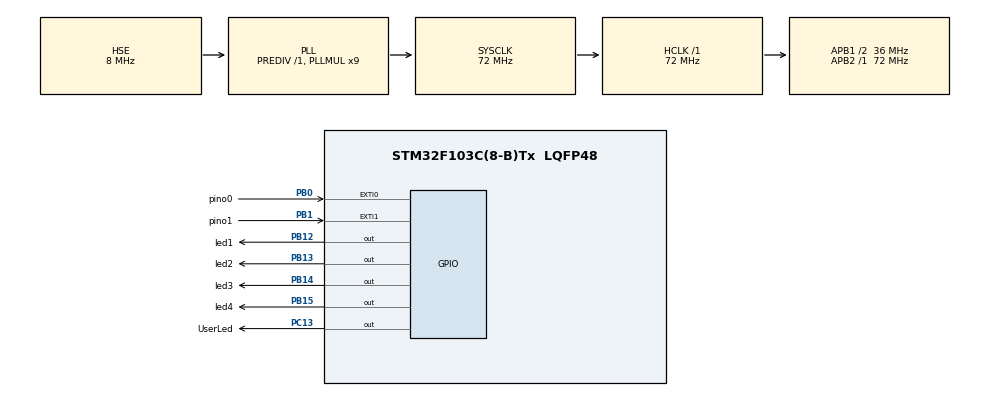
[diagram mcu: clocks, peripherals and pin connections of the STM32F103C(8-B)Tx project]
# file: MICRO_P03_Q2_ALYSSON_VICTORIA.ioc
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Mcu.Family=STM32F1
Mcu.Name=STM32F103C(8-B)Tx
Mcu.Package=LQFP48
NVIC.EXTI0_IRQn=true\:5\:0\:true\:false\:true\:true\:true\:true
NVIC.EXTI1_IRQn=true\:0\:0\:false\:false\:true\:true\:true\:true
NVIC.PriorityGroup=NVIC_PRIORITYGROUP_4
PA13.Mode=Serial_Wire
PA13.Signal=SYS_JTMS-SWDIO
PA14.Mode=Serial_Wire
PA14.Signal=SYS_JTCK-SWCLK
PB0.GPIO_Label=pino0
PB0.GPIO_ModeDefaultEXTI=GPIO_MODE_IT_FALLING
PB0.GPIO_PuPd=GPIO_PULLUP
PB0.Signal=GPXTI0
PB1.GPIO_Label=pino1
PB1.GPIO_ModeDefaultEXTI=GPIO_MODE_IT_FALLING
PB1.GPIO_PuPd=GPIO_PULLUP
PB1.Signal=GPXTI1
PB12.GPIO_Label=led1
PB12.GPIO_Speed=GPIO_SPEED_FREQ_LOW
PB12.PinState=GPIO_PIN_SET
PB12.Signal=GPIO_Output
PB13.GPIO_Label=led2
PB13.GPIO_Speed=GPIO_SPEED_FREQ_LOW
PB13.PinState=GPIO_PIN_SET
PB13.Signal=GPIO_Output
PB14.GPIO_Label=led3
PB14.GPIO_Speed=GPIO_SPEED_FREQ_LOW
PB14.PinState=GPIO_PIN_SET
PB14.Signal=GPIO_Output
PB15.GPIO_Label=led4
PB15.GPIO_Speed=GPIO_SPEED_FREQ_LOW
PB15.PinState=GPIO_PIN_SET
PB15.Signal=GPIO_Output
PC13-TAMPER-RTC.GPIO_Label=UserLed
PC13-TAMPER-RTC.PinState=GPIO_PIN_SET
PC13-TAMPER-RTC.Signal=GPIO_Output
PD0-OSC_IN.Mode=HSE-External-Oscillator
PD0-OSC_IN.Signal=RCC_OSC_IN
PD1-OSC_OUT.Mode=HSE-External-Oscillator
PD1-OSC_OUT.Signal=RCC_OSC_OUT
ProjectManager.HeapSize=0x200
ProjectManager.StackSize=0x400
ProjectManager.TargetToolchain=STM32CubeIDE
RCC.AHBFreq_Value=72000000
RCC.APB1CLKDivider=RCC_HCLK_DIV2
RCC.APB1Freq_Value=36000000
RCC.APB1TimFreq_Value=72000000
RCC.APB2Freq_Value=72000000
RCC.APB2TimFreq_Value=72000000
RCC.HCLKFreq_Value=72000000
RCC.PLLMUL=RCC_PLL_MUL9
RCC.PLLSourceVirtual=RCC_PLLSOURCE_HSE
RCC.SYSCLKFreq_VALUE=72000000
RCC.SYSCLKSource=RCC_SYSCLKSOURCE_PLLCLK
RCC.USBFreq_Value=72000000
board=custom

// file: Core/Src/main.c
/* USER CODE BEGIN Header */
/**
  ******************************************************************************
  * @file           : main.c
  * @brief          : Questão 2 - Trabalhando com interrupções
  * @author         : Alysson Lucas Pontes Cavalcante da Silva e Maria Victória Martins Neves
  * @date           : 22/04/2026
  * @details        : Aprendendo a utilizar interrupções utilizando botões e leds.
  ******************************************************************************
  */
/* USER CODE END Header */
#include "main.h"

void SystemClock_Config(void);
static void MX_GPIO_Init(void);

int main(void)
{

  /* MCU Configuration--------------------------------------------------------*/

  /* Reset of all peripherals, Initializes the Flash interface and the Systick. */
  HAL_Init();

  /* Configure the system clock */
  SystemClock_Config();

  /* Initialize all configured peripherals */
  MX_GPIO_Init();

  /* Infinite loop */
  while (1)
  {

  }
}

void SystemClock_Config(void)
{
  RCC_OscInitTypeDef RCC_OscInitStruct = {0};
  RCC_ClkInitTypeDef RCC_ClkInitStruct = {0};

  /** Initializes the RCC Oscillators according to the specified parameters
  * in the RCC_OscInitTypeDef structure.
  */
  RCC_OscInitStruct.OscillatorType = RCC_OSCILLATORTYPE_HSE;
  RCC_OscInitStruct.HSEState = RCC_HSE_ON;
  RCC_OscInitStruct.HSEPredivValue = RCC_HSE_PREDIV_DIV1;
  RCC_OscInitStruct.HSIState = RCC_HSI_ON;
  RCC_OscInitStruct.PLL.PLLState = RCC_PLL_ON;
  RCC_OscInitStruct.PLL.PLLSource = RCC_PLLSOURCE_HSE;
  RCC_OscInitStruct.PLL.PLLMUL = RCC_PLL_MUL9;
  if (HAL_RCC_OscConfig(&RCC_OscInitStruct) != HAL_OK)
  {
    Error_Handler();
  }

  /** Initializes the CPU, AHB and APB buses clocks
  */
  RCC_ClkInitStruct.ClockType = RCC_CLOCKTYPE_HCLK|RCC_CLOCKTYPE_SYSCLK
                              |RCC_CLOCKTYPE_PCLK1|RCC_CLOCKTYPE_PCLK2;
  RCC_ClkInitStruct.SYSCLKSource = RCC_SYSCLKSOURCE_PLLCLK;
  RCC_ClkInitStruct.AHBCLKDivider = RCC_SYSCLK_DIV1;
  RCC_ClkInitStruct.APB1CLKDivider = RCC_HCLK_DIV2;
  RCC_ClkInitStruct.APB2CLKDivider = RCC_HCLK_DIV1;

  if (HAL_RCC_ClockConfig(&RCC_ClkInitStruct, FLASH_LATENCY_2) != HAL_OK)
  {
    Error_Handler();
  }
}

static void MX_GPIO_Init(void)
{
  GPIO_InitTypeDef GPIO_InitStruct = {0};

  /* GPIO Ports Clock Enable */
  __HAL_RCC_GPIOC_CLK_ENABLE();
  __HAL_RCC_GPIOD_CLK_ENABLE();
  __HAL_RCC_GPIOB_CLK_ENABLE();
  __HAL_RCC_GPIOA_CLK_ENABLE();

  /*Configure GPIO pin Output Level */
  HAL_GPIO_WritePin(UserLed_GPIO_Port, UserLed_Pin, GPIO_PIN_SET);

  /*Configure GPIO pin Output Level */
  HAL_GPIO_WritePin(GPIOB, led1_Pin|led2_Pin|led3_Pin|led4_Pin, GPIO_PIN_SET);

  /*Configure GPIO pin : UserLed_Pin */
  GPIO_InitStruct.Pin = UserLed_Pin;
  GPIO_InitStruct.Mode = GPIO_MODE_OUTPUT_PP;
  GPIO_InitStruct.Pull = GPIO_NOPULL;
  GPIO_InitStruct.Speed = GPIO_SPEED_FREQ_LOW;
  HAL_GPIO_Init(UserLed_GPIO_Port, &GPIO_InitStruct);

  /*Configure GPIO pins : pino0_Pin pino1_Pin */
  GPIO_InitStruct.Pin = pino0_Pin|pino1_Pin;
  GPIO_InitStruct.Mode = GPIO_MODE_IT_FALLING;
  GPIO_InitStruct.Pull = GPIO_PULLUP;
  HAL_GPIO_Init(GPIOB, &GPIO_InitStruct);

  /*Configure GPIO pins : led1_Pin led2_Pin led3_Pin led4_Pin */
  GPIO_InitStruct.Pin = led1_Pin|led2_Pin|led3_Pin|led4_Pin;
  GPIO_InitStruct.Mode = GPIO_MODE_OUTPUT_PP;
  GPIO_InitStruct.Pull = GPIO_NOPULL;
  GPIO_InitStruct.Speed = GPIO_SPEED_FREQ_LOW;
  HAL_GPIO_Init(GPIOB, &GPIO_InitStruct);

  /* EXTI interrupt init*/
  HAL_NVIC_SetPriority(EXTI0_IRQn, 5, 0);
  HAL_NVIC_EnableIRQ(EXTI0_IRQn);

  HAL_NVIC_SetPriority(EXTI1_IRQn, 0, 0);
  HAL_NVIC_EnableIRQ(EXTI1_IRQn);

}

/* USER CODE BEGIN 4 */

/**
  * @brief  Callback de tratamento de interrupção externa (EXTI) acionada pelos botões.
  * Inverte o estado dos LEDs 1 e 2.
  * @param  GPIO_Pin Especifica o pino que gerou a interrupção.
  * @retval None
  */
void HAL_GPIO_EXTI_Callback(uint16_t GPIO_Pin)
{
	/* Verifica se a interrupção foi gerada pelo pino do SW01 */
	  if (GPIO_Pin == pino0_Pin)
	  {
	    /* Inverte o estado do LED D1 */
	    HAL_GPIO_TogglePin(led1_GPIO_Port, led1_Pin);
	  }

	  /* Verifica se a interrupção foi gerada pelo pino do SW2 */
	  else if (GPIO_Pin == pino1_Pin)
	  {
	    /* Inverte o estado do LED D2 */
	    HAL_GPIO_TogglePin(led2_GPIO_Port, led2_Pin);
	  }
}

/* USER CODE END 4 */

void Error_Handler(void)
{
  __disable_irq();
  while (1)
  {
  }
}
